# CY8C4245AXI_483 register map
File version: 0.1
PSoC 4200
Registers are 32-bit, read-write, no defined reset value unless marked. A register's access mark holds for its fields unless they carry their own. Offsets are from the block's base; lines under a group give offsets from that group; [hi:lo] are bit positions; {n}, {i} and the like mark numbered series; 'fields as' and 'values as' point back to an identical list; <NAME> marks a mode.

## Memory map
0x00000000 POFF
0x00000000 TimerADC
0x00000000 Key_Timer
0x00000000 ADC — Sequencing SAR ADC
0x00000000 OPA — OpAmp
0x00000000 DAC — IDAC
0x00000000 StatReg
0x00000000 Comp — Comparator
0x00000000 I2C — Serial Communication Block

## POFF
Base 0x00000000
0x40050108 COUNTER — Current counter value
0x4005010C CC — Compare / capture value
0x40050110 CC_BUF — Compare / capture buffer value
0x40050114 PERIOD — Period value
0x40050118 PERIOD_BUF — Period buffer value

## TimerADC
Base 0x00000000
0x40050148 COUNTER — Current counter value
0x4005014C CC — Compare / capture value
0x40050150 CC_BUF — Compare / capture buffer value
0x40050154 PERIOD — Period value
0x40050158 PERIOD_BUF — Period buffer value

## Key_Timer
Base 0x00000000
0x40050188 COUNTER — Current counter value
0x4005018C CC — Compare / capture value
0x40050190 CC_BUF — Compare / capture buffer value
0x40050194 PERIOD — Period value
0x40050198 PERIOD_BUF — Period buffer value

## OPA — OpAmp
Base 0x00000000
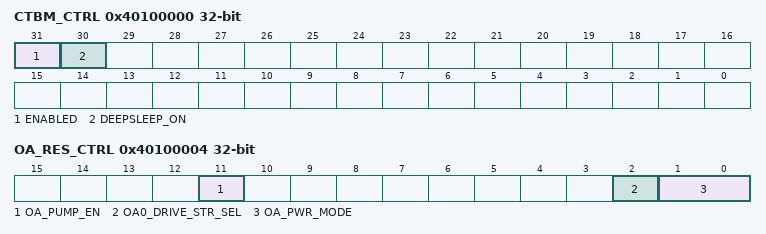
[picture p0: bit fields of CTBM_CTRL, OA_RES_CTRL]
0x40100000 CTBM_CTRL — Global CTB IP and power control
  [31] ENABLED — Selects component behavior in DeepSleep power mode
    0=DISABLE (CTB IP disabled (put analog in power down, open all switches)); 1=ENABLE (CTB IP enabledCTB IP enabled)
  [30] DEEPSLEEP_ON — Selects component behavior in DeepSleep power mode
    0=DISABLE (CTB IP disabled off during DeepSleep power mode); 1=ENABLE (CTB IP remains enabled during DeepSleep power mode (if ENABLED=1))
0x40100004 OA_RES_CTRL — Opamp and resistor control
  [11] OA_PUMP_EN — Selects pump
    0=DISABLE (Pump disabled); 1=ENABLE (Pump enabled)
  [2] OA0_DRIVE_STR_SEL — Opamp output strenght select
    0=Cy1x (Internal only); 1=Cy10x (Output to pin)
  [1:0] OA_PWR_MODE — Selects power for opamp
    0=OFF; 1=LOW (Low power); 2=MED (Medium power); 3=HIGH (High power)
0x40100F08 OA_COMP_TRIM — Opamp Compenation Capacitor Trim
  [1:0] OA_COMP_TRIM
    1=HIGH_SPEED; 2=BALANCED; 3=HIGH_STABILITY

## DAC — IDAC
Base 0x00000000
0x40080004 CSD_IDAC_POLARITY
0x40080008 CSD_IDAC
0x4008FF00 CSD_TRIM1 — CSD IDAC TRIM1
0x4008FF04 CSD_TRIM2 — CSD IDAC TRIM2

## StatReg
Base 0x00000000
0x400F0063 StatReg_STATUS_REG 8-bit
0x400F0083 StatReg_MASK_REG 8-bit
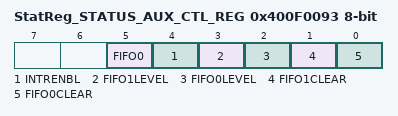
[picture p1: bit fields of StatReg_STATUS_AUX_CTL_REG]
0x400F0093 StatReg_STATUS_AUX_CTL_REG 8-bit
  [5] FIFO0 — FIFO0 clear
    1=ENABLED (Enable counter); 0=DISABLED (Disable counter)
  [4] INTRENBL — Enables or disables the Interrupt
    1=ENABLED (Interrupt enabled); 0=DISABLED (Interrupt disabled)
  [3] FIFO1LEVEL — FIFO level
    1=ENABLED (FIFO LVL: input mode: FIFO at least 1/2 empty; output mode: FIFO at least 1/2 full); 0=DISABLED (FIFO LVL: input mode: FIFO not full; output mode: FIFO not empty)
  [2] FIFO0LEVEL — FIFO level
    values as FIFO1LEVEL
  [1] FIFO1CLEAR — FIFO clear
    1=ENABLED (Clear FIFO state); 0=DISABLED (Normal FIFO operation)
  [0] FIFO0CLEAR — FIFO clear
    values as FIFO1CLEAR

## Comp — Comparator
Base 0x00000000
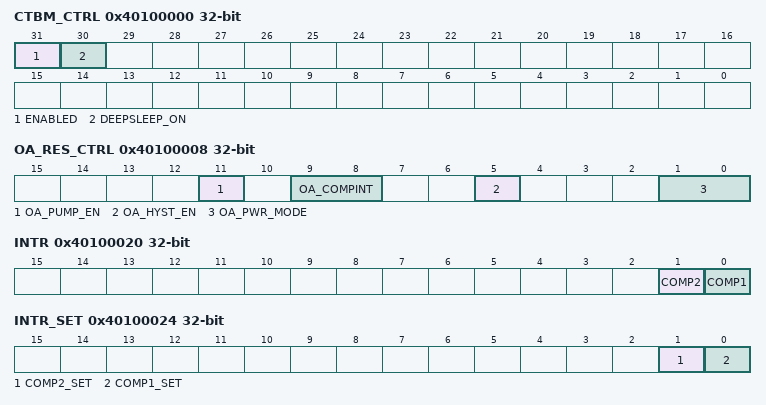
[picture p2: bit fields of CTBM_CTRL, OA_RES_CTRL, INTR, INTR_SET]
0x40100000 CTBM_CTRL — Global CTB IP and power control
  [31] ENABLED — Selects component behavior in DeepSleep power mode
    0=DISABLE (CTB IP disabled (put analog in power down, open all switches)); 1=ENABLE (CTB IP enabledCTB IP enabled)
  [30] DEEPSLEEP_ON — Selects component behavior in DeepSleep power mode
    0=DISABLE (CTB IP disabled off during DeepSleep power mode); 1=ENABLE (CTB IP remains enabled during DeepSleep power mode (if ENABLED=1))
0x40100008 OA_RES_CTRL — Comparator and resistor control
  [11] OA_PUMP_EN — Selects pump
    0=DISABLE (Pump disabled); 1=ENABLE (Pump enabled)
  [9:8] OA_COMPINT — Selects comparator edge detect
    0=DISABLE (Disabled); 1=RISING (Rising edge); 2=FALLING (Falling edge); 3=BOTH (Both rising and falling edges)
  [5] OA_HYST_EN — Selects hysteresis (10mV)
    0=DISABLE (Hysteresis disabled); 1=ENABLE (Hysteresis enabled)
  [1:0] OA_PWR_MODE — Selects speed for comparator
    0=OFF; 1=SLOW (Slow speed); 2=MED (Medium speed); 3=FAST (Fast speed)
0x4010000C COMP_STAT — Comparator status
  [16] OA_COMP ro — Current comparator status
0x40100020 INTR — Interrupt request register
  [1] COMP2 — Comparator #2 Interrupt: hardware sets this interrupt when comparator 0 triggers. Write with '1' to clear bit.
  [0] COMP1 — Comparator #1 Interrupt: hardware sets this interrupt when comparator 0 triggers. Write with '1' to clear bit.
0x40100024 INTR_SET — Interrupt request set register
  [1] COMP2_SET — Write with '1' to set corresponding bit in interrupt request register.
  [0] COMP1_SET — Write with '1' to set corresponding bit in interrupt request register.
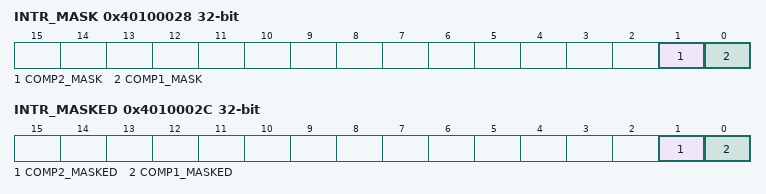
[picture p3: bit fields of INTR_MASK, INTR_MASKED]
0x40100028 INTR_MASK — Interrupt request mask
  [1] COMP2_MASK — Mask bit for corresponding bit in interrupt request register.
  [0] COMP1_MASK — Mask bit for corresponding bit in interrupt request register.
0x4010002C INTR_MASKED — Interrupt request masked
  [1] COMP2_MASKED ro — Logical and of corresponding request and mask bits.
  [0] COMP1_MASKED ro — Logical and of corresponding request and mask bits.
0x40100F0C OA_OFFSET_TRIM — Comparator offset trim
0x40100F10 OA_SLOPE_OFFSET_TRIM — Comparator slope offset drift trim
0x40100F14 OA_COMP_TRIM — Comparator trim
